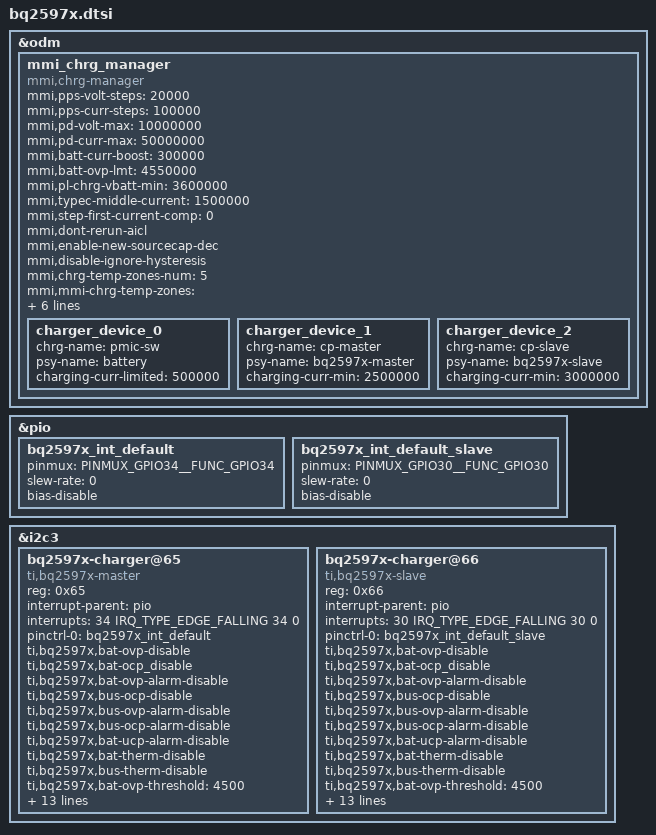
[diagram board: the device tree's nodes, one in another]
&odm {
	 status = "okay";

        mmi_chrg_manager {
                status = "ok";
                compatible = "mmi,chrg-manager";
                //qcom,usbpd-phandle = <&pm6150_pdphy>;
                mmi,pps-volt-steps = <20000>;
                mmi,pps-curr-steps = <100000>;
                mmi,pd-volt-max = <10000000>;
                mmi,pd-curr-max = <50000000>;
                mmi,batt-curr-boost = <300000>;
                mmi,batt-ovp-lmt = <4550000>;
                mmi,pl-chrg-vbatt-min = <3600000>;
                mmi,typec-middle-current = <1500000>;
                mmi,step-first-current-comp = <0>;
                mmi,dont-rerun-aicl;
		mmi,enable-new-sourcecap-dec;
		mmi,disable-ignore-hysteresis;
                mmi,chrg-temp-zones-num = <5>;
                mmi,mmi-chrg-temp-zones =
					<0 4200 970  0 0 0 0 0 0>,
					<10 4450 2425 0 0 0 0 0 0>,
					<15 4450 4850 0 0 0 0 0 0>,
					<45 4170 9800 4270 8000 4360 6000 4450 4000>,
					<60 4200 4850 0 0 0 0 0 0>;
		mmi,thermal-min-level = <2000000>;
                charger_device_0 {
                        chrg-name = "pmic-sw";
                        psy-name = "battery";
                        charging-curr-limited = <500000>;
                };
                charger_device_1 {
                        chrg-name = "cp-master";
                        psy-name = "bq2597x-master";
                        charging-curr-min = <2500000>;
                };
                charger_device_2 {
                        chrg-name = "cp-slave";
                        psy-name = "bq2597x-slave";
                        charging-curr-min = <3000000>;
                };

        };
};

&pio {
	bq2597x_int_default: bq2597x_int_default {
		pinmux = <PINMUX_GPIO34__FUNC_GPIO34>;
		slew-rate= <0>;
		bias-disable;
	};
	bq2597x_int_default_slave: bq2597x_int_default_slave {
                pinmux = <PINMUX_GPIO30__FUNC_GPIO30>;
                slew-rate= <0>;
                bias-disable;
        };

};

&i2c3 {
	status = "okay";
	bq2597x-charger@65 {
		compatible = "ti,bq2597x-master";
		reg = <0x65>;
		//ti,bq2597x,interrupt_gpios = <&pio 34 0>;
		interrupt-parent = <&pio>;
		interrupts = <34 IRQ_TYPE_EDGE_FALLING 34 0>;
		interrupt-names = "bq2597x_irq";
		pinctrl-names = "default";
		pinctrl-0 = <&bq2597x_int_default>;
		ti,bq2597x,bat-ovp-disable;
		ti,bq2597x,bat-ocp_disable;
		ti,bq2597x,bat-ovp-alarm-disable;
		ti,bq2597x,bus-ocp-disable;
		ti,bq2597x,bus-ovp-alarm-disable;
		ti,bq2597x,bus-ocp-alarm-disable;
		ti,bq2597x,bat-ucp-alarm-disable;
		ti,bq2597x,bat-therm-disable;
		ti,bq2597x,bus-therm-disable;

		ti,bq2597x,bat-ovp-threshold = <4500>;
		ti,bq2597x,bat-ovp-alarm-threshold = <4450>;
		ti,bq2597x,bat-ocp-threshold = <10000>;
		ti,bq2597x,bat-ocp-alarm-threshold = <9800>;

		ti,bq2597x,bus-ovp-threshold = <12000>;
		ti,bq2597x,bus-ovp-alarm-threshold = <11000>;
		ti,bq2597x,bus-ocp-threshold = <3750>;
		ti,bq2597x,bus-ocp-alarm-threshold = <3500>;

		ti,bq2597x,bat-ucp-alarm-threshold = <2000>;

		ti,bq2597x,bat-therm-threshold = <0x15>;
		ti,bq2597x,bus-therm-threshold = <0x15>;
		ti,bq2597x,die-therm-threshold = <125>;

		ti,bq2597x,ac-ovp-threshold = <17>;
		ti,bq2597x,sense-resistor-mohm = <5>;
	};

	bq2597x-charger@66 {
		compatible = "ti,bq2597x-slave";
		reg = <0x66>;
		//ti,bq2597x,interrupt_gpios = <&pio 30 0>;
		interrupt-parent = <&pio>;
		interrupts = <30 IRQ_TYPE_EDGE_FALLING 30 0>;
		interrupt-names = "bq2597x_irq";
		pinctrl-names = "default_slave";
		pinctrl-0 = <&bq2597x_int_default_slave>;
		ti,bq2597x,bat-ovp-disable;
		ti,bq2597x,bat-ocp_disable;
		ti,bq2597x,bat-ovp-alarm-disable;
		ti,bq2597x,bus-ocp-disable;
		ti,bq2597x,bus-ovp-alarm-disable;
		ti,bq2597x,bus-ocp-alarm-disable;
		ti,bq2597x,bat-ucp-alarm-disable;
		ti,bq2597x,bat-therm-disable;
		ti,bq2597x,bus-therm-disable;

		ti,bq2597x,bat-ovp-threshold = <4500>;
		ti,bq2597x,bat-ovp-alarm-threshold = <4450>;
		ti,bq2597x,bat-ocp-threshold = <8000>;
		ti,bq2597x,bat-ocp-alarm-threshold = <7500>;

		ti,bq2597x,bus-ovp-threshold = <12000>;
		ti,bq2597x,bus-ovp-alarm-threshold = <11000>;
		ti,bq2597x,bus-ocp-threshold = <3750>;
		ti,bq2597x,bus-ocp-alarm-threshold = <3500>;

		ti,bq2597x,bat-ucp-alarm-threshold = <2000>;

		ti,bq2597x,bat-therm-threshold = <0x15>;
		ti,bq2597x,bus-therm-threshold = <0x15>;
		ti,bq2597x,die-therm-threshold = <125>;

		ti,bq2597x,ac-ovp-threshold = <17>;
		ti,bq2597x,sense-resistor-mohm = <5>;
	};
};

